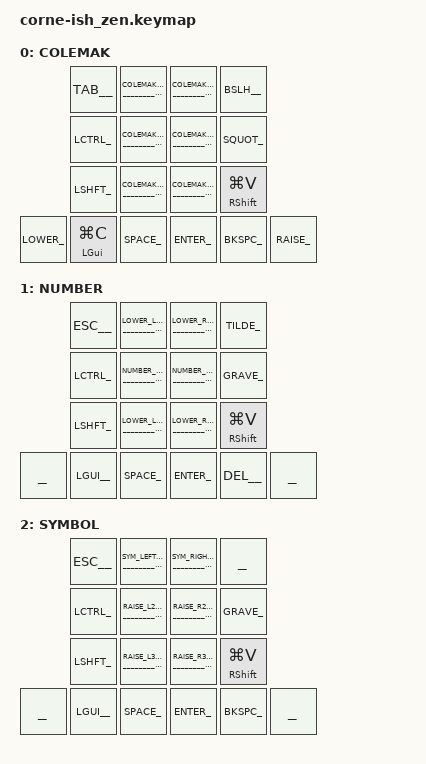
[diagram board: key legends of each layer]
/*
 *
 * Copyright (c) 2021 Darryl deHaan
 * SPDX-License-Identifier: MIT
 *
 */

#include <behaviors.dtsi>
#include <dt-bindings/zmk/keys.h>
#include <dt-bindings/zmk/bt.h>
#include "keycodes.h"
#include "wrappers.h"

&sl {
        release-after-ms = <2000>;
        quick-release;
};

/ {
        behaviors {
                as: auto_shift {
                        compatible = "zmk,behavior-hold-tap";
                        label = "AUTO_SHIFT";
                        #binding-cells = <2>;
                        tapping-term-ms = <220>;
                        quick-tap-ms = <0>;
                        flavor = "tap-preferred";
                        bindings = <&kp>, <&kp>;
                };
                hld: tap_cmd {
                        compatible = "zmk,behavior-hold-tap";
                        label = "HOLD_TAP";
                        #binding-cells = <2>;
                        tapping-term-ms = <180>;
                        quick-tap-ms = <0>;
                        flavor = "tap-preferred";
                        bindings = <&kp>, <&kp>;
                };
        };

        keymap {
                compatible = "zmk,keymap";

                default_layer {
                        label = "COLEMAK";
                        // -------------------------------------------     -------------------------------------------
                        // |  TAB |   Q  |   W  |   F  |   P  |   B  |     |   J  |   L  |   U  |   Y  |   ;  |  \   |
                        // |LCTRL |   A  |   R  |   S  |   T  |   G  |     |   M  |   N  |   E  |   I  |   O  |  '   |
                        // |LSHFT |   Z  |   X  |   C  |   D  |   V  |     |   K  |   H  |   ,  |   .  |   /  |RSH/PS|
                        // `-----------------------------------------/     \-----------------------------------------'
                        //                      | LWR  |GUI/CP| SPC  |     | ENT  |BKSPC |RAISE |
                        //                      ----------------------     ----------------------
                        bindings = <
                        __TAB__ _________________COLEMAK_L1________________  _________________COLEMAK_R1________________ _BSLH__
                        _LCTRL_ _________________COLEMAK_L2________________  _________________COLEMAK_R2________________ _SQUOT_
                        _LSHFT_ _________________COLEMAK_L3________________  _________________COLEMAK_R3________________ &hld RIGHT_SHIFT LG(V)
                                          _LOWER_  &hld LGUI LG(C)  _SPACE_  _ENTER_  _BKSPC_  _RAISE_
                        >;
                };

                lower_layer {
                        label = "NUMBER";
                        // -------------------------------------------     -------------------------------------------
                        // |ESC   |  F1  |  F2  |  F3  |  F4  |  F5  |     |  F6  |  F7  |  F8  |  F9  | F10  |   ~  |
                        // |LCTRL |   1  |   2  |   3  |   4  |   5  |     |   6  |   7  |   8  |   9  |   0  |   `  |
                        // |LSHFT |      |      |      |      |      |     |  +   |  _   | "|"  |   {  |   }  |RSH/PS|
                        // `-----------------------------------------/     \-----------------------------------------'
                        //                      |      |  GUI | SPC  |     | ENT  | DEL  |      |
                        //                      ----------------------     ----------------------
                        bindings = <
                        __ESC__ _________________LOWER_L2__________________  _________________LOWER_R2__________________ _TILDE_
                        _LCTRL_ ________________NUMBER_LEFT________________  ________________NUMBER_RIGHT_______________ _GRAVE_
                        _LSHFT_ _________________LOWER_L3__________________  _________________LOWER_R3__________________ &hld RIGHT_SHIFT LG(V)
                                                  _______  _LGUI__  _SPACE_  _ENTER_  __DEL__  _______
                        >;
                };

                raise_layer {
                        label = "SYMBOL";
                        // -------------------------------------------     -------------------------------------------
                        // |  TAB |  !   |  @   |  #   |  $   |  %   |     |  ^   |  &   |  *   |  (   |  )   |      |
                        // |LCTRL |      |      | PLAY | PREV | NEXT |     |      | left |  up  | down |right |  `   |
                        // |LSHFT |      |      | MUTE |VOLUP |VOLDN |     |  =   |  -   |      |  [   |  ]   |RSH/PS|
                        // `-----------------------------------------/     \-----------------------------------------'
                        //                      |      |  GUI | SPC  |     | ENT  | BSPC |      |
                        //                      ----------------------     ----------------------
                        bindings = <
                        __ESC__ _________________SYM_LEFT__________________  _________________SYM_RIGHT_________________ _______
                        _LCTRL_ _________________RAISE_L2__________________  _________________RAISE_R2__________________ _GRAVE_
                        _LSHFT_ _________________RAISE_L3__________________  _________________RAISE_R3__________________ &hld RIGHT_SHIFT LG(V)
                                                  _______  _LGUI__  _SPACE_  _ENTER_  _BKSPC_  _______
                        >;
                };
        };
};
